# ATSAM3X8H register map
Vendor: Atmel; Series: SAM3X; File version: 0
CPU: CM3 r2p0, selectable endian, MPU, no FPU, 4 interrupt priority bits
Registers are 32-bit, read-write, reset 0x0 unless marked. A register's access mark holds for its fields unless they carry their own. Offsets are from the block's base; [hi:lo] are bit positions; {n}, {i} and the like mark numbered series; 'fields as' and 'values as' point back to an identical list.

## SDRAMC — SDRAM Controller
Base 0x400E0200; register names take the prefix SDRAMC_
0x00 MR — SDRAMC Mode Register
  [2:0] MODE — SDRAMC Command Mode
    0=NORMAL (Normal mode. Any access to the SDRAM is decoded normally. To activate this mode, command must be followed by a write to the SDRAM.); 1=NOP (The SDRAM Controller issues a NOP command when the SDRAM device is accessed regardless of the cycle. To activate this mode, command must be followed by a write to the SDRAM.); 2=ALLBANKS_PRECHARGE (The SDRAM Controller issues an "All Banks Precharge" command when the SDRAM device is accessed regardless of the cycle. To activate this mode, command must be followed by a write to the SDRAM.); 3=LOAD_MODEREG (The SDRAM Controller issues a "Load Mode Register" command when the SDRAM device is accessed regardless of the cycle. To activate this mode, command must be followed by a write to the SDRAM.); 4=AUTO_REFRESH (The SDRAM Controller issues an "Auto-Refresh" Command when the SDRAM device is accessed regardless of the cycle. Previously, an "All Banks Precharge" command must be issued. To activate this mode, command must be followed by a write to the SDRAM.); 5=EXT_LOAD_MODEREG (The SDRAM Controller issues an "Extended Load Mode Register" command when the SDRAM device is accessed regardless of the cycle. To activate this mode, the "Extended Load Mode Register" command must be followed by a write to the SDRAM. The write in the SDRAM must be done in the appropriate bank; most low-power SDRAM devices use the bank 1.); 6=DEEP_POWERDOWN (Deep power-down mode. Enters deep power-down mode.)
0x04 TR — SDRAMC Refresh Timer Register
  [11:0] COUNT — SDRAMC Refresh Timer Count
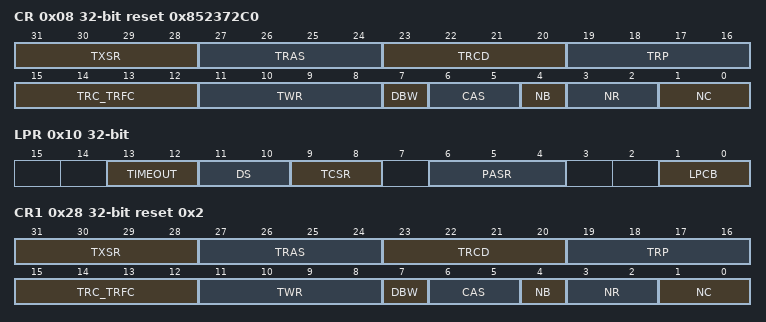
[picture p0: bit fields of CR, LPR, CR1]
0x08 CR reset 0x852372C0 — SDRAMC Configuration Register
  [31:28] TXSR — Exit Self Refresh to Active Delay
  [27:24] TRAS — Active to Precharge Delay
  [23:20] TRCD — Row to Column Delay
  [19:16] TRP — Row Precharge Delay
  [15:12] TRC_TRFC — Row Cycle Delay and Row Refresh Cycle
  [11:8] TWR — Write Recovery Delay
  [7] DBW — Data Bus Width
  [6:5] CAS — CAS Latency
    1=LATENCY1 (1 cycle CAS latency); 2=LATENCY2 (2 cycle CAS latency); 3=LATENCY3 (3 cycle CAS latency)
  [4] NB — Number of Banks
    0=BANK2 (2 banks); 1=BANK4 (4 banks)
  [3:2] NR — Number of Row Bits
    0=ROW11 (11 row bits); 1=ROW12 (12 row bits); 2=ROW13 (13 row bits)
  [1:0] NC — Number of Column Bits
    {v}=COL{v+8} ({v+8} column bits) (v=0..3)
0x10 LPR — SDRAMC Low Power Register
  [13:12] TIMEOUT — Time to define when low-power mode is enable
    0=LP_LAST_XFER (The SDRAM controller activates the SDRAM low-power mode immediately after the end of the last transfer.); 1=LP_LAST_XFER_64 (The SDRAM controller activates the SDRAM low-power mode 64 clock cycles after the end of the last transfer.); 2=LP_LAST_XFER_128 (The SDRAM controller activates the SDRAM low-power mode 128 clock cycles after the end of the last transfer.)
  [11:10] DS — Drive Strength (only for low-power SDRAM)
  [9:8] TCSR — Temperature Compensated Self-Refresh (only for low-power SDRAM)
  [6:4] PASR — Partial Array Self-refresh (only for low-power SDRAM)
  [1:0] LPCB — Low-power Configuration Bits
    0=DISABLED (Low Power Feature is inhibited: no Power-down, Self-refresh or Deep Power-down command is issued to the SDRAM device.); 1=SELF_REFRESH (The SDRAM Controller issues a Self-refresh command to the SDRAM device, the SDCK clock is deactivated and the SDCKE signal is set low. The SDRAM device leaves the Self Refresh Mode when accessed and enters it after the access.); 2=POWER_DOWN (The SDRAM Controller issues a Power-down Command to the SDRAM device after each access, the SDCKE signal is set to low. The SDRAM device leaves the Power-down Mode when accessed and enters it after the access.); 3=DEEP_POWER_DOWN (The SDRAM Controller issues a Deep Power-down command to the SDRAM device. This mode is unique to low-power SDRAM.)
0x14 IER wo reset not defined — SDRAMC Interrupt Enable Register
  [0] RES — Refresh Error Status
0x18 IDR wo reset not defined — SDRAMC Interrupt Disable Register
  [0] RES — Refresh Error Status
0x1C IMR ro — SDRAMC Interrupt Mask Register
  [0] RES — Refresh Error Status
0x20 ISR ro — SDRAMC Interrupt Status Register
  [0] RES — Refresh Error Status
0x24 MDR — SDRAMC Memory Device Register
  [1:0] MD — Memory Device Type
    0=SDRAM; 1=LPSDRAM (Low-power SDRAM)
0x28 CR1 reset 0x2 — SDRAMC Configuration Register 1
  fields as CR
0x2C OCMS — SDRAMC OCMS Register 1
  [0] SDR_SE — SDRAM Memory Controller Scrambling Enable

## Notices in the file
SAM Software Package License
Copyright (c) %copyright_year%, Atmel Corporation
All rights reserved.
Redistribution and use in source and binary forms, with or without
modification, are permitted provided that the following condition is met:
- Redistributions of source code must retain the above copyright notice,
this list of conditions and the disclaimer below.
Atmel's name may not be used to endorse or promote products derived from
this software without specific prior written permission.
DISCLAIMER:  THIS SOFTWARE IS PROVIDED BY ATMEL "AS IS" AND ANY EXPRESS OR
IMPLIED WARRANTIES, INCLUDING, BUT NOT LIMITED TO, THE IMPLIED WARRANTIES OF
MERCHANTABILITY, FITNESS FOR A PARTICULAR PURPOSE AND NON-INFRINGEMENT ARE
DISCLAIMED. IN NO EVENT SHALL ATMEL BE LIABLE FOR ANY DIRECT, INDIRECT,
INCIDENTAL, SPECIAL, EXEMPLARY, OR CONSEQUENTIAL DAMAGES (INCLUDING, BUT NOT
LIMITED TO, PROCUREMENT OF SUBSTITUTE GOODS OR SERVICES; LOSS OF USE, DATA,
OR PROFITS; OR BUSINESS INTERRUPTION) HOWEVER CAUSED AND ON ANY THEORY OF
LIABILITY, WHETHER IN CONTRACT, STRICT LIABILITY, OR TORT (INCLUDING
NEGLIGENCE OR OTHERWISE) ARISING IN ANY WAY OUT OF THE USE OF THIS SOFTWARE,
EVEN IF ADVISED OF THE POSSIBILITY OF SUCH DAMAGE.
